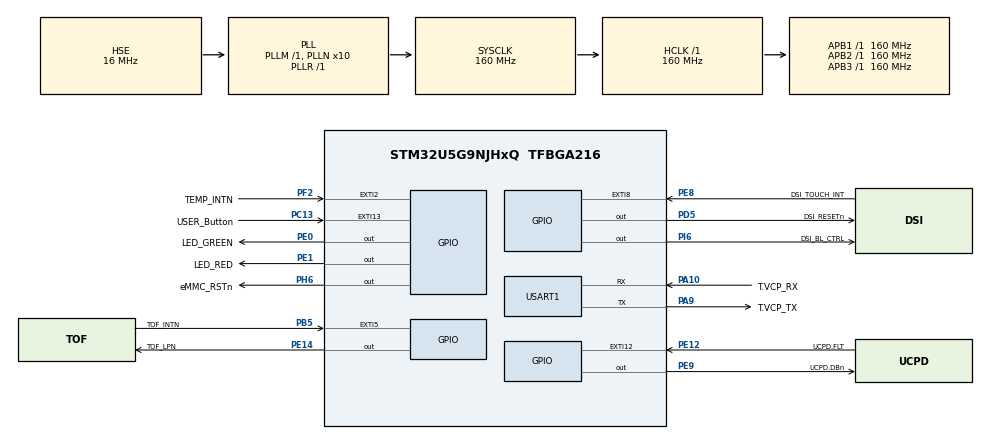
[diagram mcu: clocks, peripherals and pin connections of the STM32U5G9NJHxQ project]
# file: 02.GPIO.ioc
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CORTEX_M33_NS.MPU_Control=__NULL
CORTEX_M33_NS.userName=CORTEX_M33
Mcu.Family=STM32U5
Mcu.Name=STM32U5G9NJHxQ
Mcu.Package=TFBGA216
NVIC.EXTI13_IRQn=true\:0\:0\:false\:false\:true\:true\:true\:true
NVIC.PriorityGroup=NVIC_PRIORITYGROUP_4
NVIC.USART1_IRQn=true\:0\:0\:false\:false\:true\:true\:true\:true
PA10.GPIO_Label=T.VCP_RX
PA10.Mode=Asynchronous
PA10.Signal=USART1_RX
PA11.Signal=USB_OTG_HS_DM
PA12.Signal=USB_OTG_HS_DP
PA13\ (JTMS/SWDIO).Signal=DEBUG_JTMS-SWDIO
PA14\ (JTCK/SWCLK).Signal=DEBUG_JTCK-SWCLK
PA9.GPIO_Label=T.VCP_TX
PA9.Mode=Asynchronous
PA9.Signal=USART1_TX
PB5.GPIO_Label=TOF_INTN
PB5.Signal=GPXTI5
PC13.GPIO_Label=USER_Button
PC13.GPIO_PuPd=GPIO_NOPULL
PC13.Signal=GPXTI13
PC14-OSC32_IN\ (PC14).Mode=LSE-External-Oscillator
PC14-OSC32_IN\ (PC14).Signal=RCC_OSC32_IN
PC15-OSC32_OUT\ (PC15).Mode=LSE-External-Oscillator
PC15-OSC32_OUT\ (PC15).Signal=RCC_OSC32_OUT
PD5.GPIO_Label=DSI_RESETn
PD5.Signal=GPIO_Output
PE0.GPIO_Label=LED_GREEN
PE0.Signal=GPIO_Output
PE1.GPIO_Label=LED_RED
PE1.Signal=GPIO_Output
PE12.GPIO_Label=UCPD.FLT
PE12.Signal=GPXTI12
PE14.GPIO_Label=TOF_LPN
PE14.Signal=GPIO_Output
PE8.GPIO_Label=DSI_TOUCH_INT
PE8.Signal=GPXTI8
PE9.GPIO_Label=UCPD.DBn
PE9.Signal=GPIO_Output
PF2.GPIO_Label=TEMP_INTN
PF2.Signal=GPXTI2
PG1.GPIO_Label=VBUS_SENSE
PG1.Signal=ADC4_IN8
PH0-OSC_IN\ (PH0).Mode=HSE-External-Oscillator
PH0-OSC_IN\ (PH0).Signal=RCC_OSC_IN
PH1-OSC_OUT\ (PH1).Mode=HSE-External-Oscillator
PH1-OSC_OUT\ (PH1).Signal=RCC_OSC_OUT
PH10.Signal=HSPI1_IO0
PH11.Signal=HSPI1_IO1
PH12.Signal=HSPI1_IO2
PH13.Signal=HSPI1_IO3
PH14.Signal=HSPI1_IO4
PH15.Signal=HSPI1_IO5
PH6.GPIO_Label=eMMC_RSTn
PH6.Signal=GPIO_Output
PH9.Signal=HSPI1_NCS
PI0.Signal=HSPI1_IO6
PI1.Signal=HSPI1_IO7
PI10.Signal=HSPI1_IO9
PI11.Signal=HSPI1_IO10
PI12.Signal=HSPI1_IO11
PI13.Signal=HSPI1_IO12
PI14.Signal=HSPI1_IO13
PI15.Signal=HSPI1_IO14
PI2.Signal=HSPI1_DQS0
PI3.Signal=HSPI1_CLK
PI6.GPIO_Label=DSI_BL_CTRL
PI6.Signal=GPIO_Output
PI8.Signal=HSPI1_DQS1
PI9.Signal=HSPI1_IO8
PJ0.Signal=HSPI1_IO15
PWR.PowerMode=PWR_SMPS_SUPPLY
PWR.pwrPrivilege=PWR_PRIVILEGE_NO
ProjectManager.HeapSize=0x200
ProjectManager.StackSize=0x400
ProjectManager.TargetToolchain=STM32CubeIDE
RCC.ADCFreq_Value=16000000
RCC.AHBFreq_Value=160000000
RCC.APB1Freq_Value=160000000
RCC.APB1TimFreq_Value=160000000
RCC.APB2Freq_Value=160000000
RCC.APB2TimFreq_Value=160000000
RCC.APB3Freq_Value=160000000
RCC.CortexFreq_Value=160000000
RCC.EPOD_VALUE=16000000
RCC.HCLKFreq_Value=160000000
RCC.HSE_VALUE=16000000
RCC.HSI48_VALUE=48000000
RCC.HSI_VALUE=16000000
RCC.LSIDIV_VALUE=32000
RCC.MSIClockRange=RCC_MSIRANGE_0
RCC.MSI_VALUE=48000000
RCC.PLL1P=8
RCC.PLL1R=1
RCC.PLL2FRACN=0
RCC.PLL3FRACN=0
RCC.PLLFRACN=0
RCC.PLLN=10
RCC.PLLSourceVirtual=RCC_PLLSOURCE_HSE
RCC.SYSCLKFreq_VALUE=160000000
RCC.SYSCLKSource=RCC_SYSCLKSOURCE_PLLCLK
RCC.VCOOutputFreq_Value=160000000
USART1.VirtualMode-Asynchronous=VM_ASYNC
VP_ICACHE_VS_ICACHE.Mode=DirectMappedCache
VP_LPBAMQUEUE_VS_QUEUE.Mode=QUEUEMODE
VP_LPBAM_VS_SIG1.Mode=SmartRun
VP_LPBAM_VS_SIG4.Mode=LPDMA1
VP_MEMORYMAP_VS_MEMORYMAP.Mode=CurAppReg
VP_PWR_VS_LPOM.Mode=PowerOptimisation
VP_PWR_VS_SECSignals.Mode=Security/Privilege
board=STM32U5G9J-DK1

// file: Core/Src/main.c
/* USER CODE BEGIN Header */
/**
  ******************************************************************************
  * @file           : main.c
  * @brief          : Main program body
  ******************************************************************************
  * @attention
  *
  * Copyright (c) 2024 STMicroelectronics.
  * All rights reserved.
  *
  * This software is licensed under terms that can be found in the LICENSE file
  * in the root directory of this software component.
  * If no LICENSE file comes with this software, it is provided AS-IS.
  *
  ******************************************************************************
  */
/* USER CODE END Header */
#include "main.h"
#include "icache.h"
#include "memorymap.h"
#include "usart.h"
#include "gpio.h"

/* USER CODE BEGIN Includes */
#include "stdio.h"
#include "string.h"
/* USER CODE END Includes */

/* USER CODE BEGIN PV */
int mode = 0;
/* USER CODE END PV */

void SystemClock_Config(void);
static void SystemPower_Config(void);

/* USER CODE BEGIN 0 */
int _write(int file, char* pData, int len)
{

	//HAL_UART_Transmit(&huart1, (uint8_t*)pData, len, 10);
	return len;
}

void HAL_GPIO_EXTI_Rising_Callback(uint16_t GPIO_Pin)
{
	if(GPIO_Pin == USER_Button_Pin)
	{
		//mode = 1;
		HAL_GPIO_TogglePin(GPIOE, LED_RED_Pin);
	}
}
//void HAL_GPIO_EXTI_Falling_Callback(uint16_t GPIO_Pin)
//{
//
//}
/* USER CODE END 0 */

int main(void)
{

  /* MCU Configuration--------------------------------------------------------*/

  /* Reset of all peripherals, Initializes the Flash interface and the Systick. */
  HAL_Init();

  /* Configure the System Power */
  SystemPower_Config();

  /* Configure the system clock */
  SystemClock_Config();

  /* Initialize all configured peripherals */
  MX_GPIO_Init();
  MX_ICACHE_Init();
  MX_USART1_UART_Init();

  /* Infinite loop */
  /* USER CODE BEGIN WHILE */
  while (1)
  {
	  HAL_GPIO_TogglePin(GPIOE, LED_GREEN_Pin);
	  HAL_Delay(500);
	  if(mode == 1 )
	  {
		  //HAL_GPIO_TogglePin(GPIOE, LED_RED_Pin);
	  }
    /* USER CODE END WHILE */

  }
}

void SystemClock_Config(void)
{
  RCC_OscInitTypeDef RCC_OscInitStruct = {0};
  RCC_ClkInitTypeDef RCC_ClkInitStruct = {0};

  /** Configure the main internal regulator output voltage
  */
  if (HAL_PWREx_ControlVoltageScaling(PWR_REGULATOR_VOLTAGE_SCALE1) != HAL_OK)
  {
    Error_Handler();
  }

  /** Initializes the CPU, AHB and APB buses clocks
  */
  RCC_OscInitStruct.OscillatorType = RCC_OSCILLATORTYPE_HSE;
  RCC_OscInitStruct.HSEState = RCC_HSE_ON;
  RCC_OscInitStruct.PLL.PLLState = RCC_PLL_ON;
  RCC_OscInitStruct.PLL.PLLSource = RCC_PLLSOURCE_HSE;
  RCC_OscInitStruct.PLL.PLLMBOOST = RCC_PLLMBOOST_DIV1;
  RCC_OscInitStruct.PLL.PLLM = 1;
  RCC_OscInitStruct.PLL.PLLN = 10;
  RCC_OscInitStruct.PLL.PLLP = 8;
  RCC_OscInitStruct.PLL.PLLQ = 2;
  RCC_OscInitStruct.PLL.PLLR = 1;
  RCC_OscInitStruct.PLL.PLLRGE = RCC_PLLVCIRANGE_1;
  RCC_OscInitStruct.PLL.PLLFRACN = 0;
  if (HAL_RCC_OscConfig(&RCC_OscInitStruct) != HAL_OK)
  {
    Error_Handler();
  }

  /** Initializes the CPU, AHB and APB buses clocks
  */
  RCC_ClkInitStruct.ClockType = RCC_CLOCKTYPE_HCLK|RCC_CLOCKTYPE_SYSCLK
                              |RCC_CLOCKTYPE_PCLK1|RCC_CLOCKTYPE_PCLK2
                              |RCC_CLOCKTYPE_PCLK3;
  RCC_ClkInitStruct.SYSCLKSource = RCC_SYSCLKSOURCE_PLLCLK;
  RCC_ClkInitStruct.AHBCLKDivider = RCC_SYSCLK_DIV1;
  RCC_ClkInitStruct.APB1CLKDivider = RCC_HCLK_DIV1;
  RCC_ClkInitStruct.APB2CLKDivider = RCC_HCLK_DIV1;
  RCC_ClkInitStruct.APB3CLKDivider = RCC_HCLK_DIV1;

  if (HAL_RCC_ClockConfig(&RCC_ClkInitStruct, FLASH_LATENCY_4) != HAL_OK)
  {
    Error_Handler();
  }
}

/**
  * @brief Power Configuration
  * @retval None
  */
static void SystemPower_Config(void)
{

  /*
   * Switch to SMPS regulator instead of LDO
   */
  if (HAL_PWREx_ConfigSupply(PWR_SMPS_SUPPLY) != HAL_OK)
  {
    Error_Handler();
  }
}

void Error_Handler(void)
{
  __disable_irq();
  while (1)
  {
  }
}
